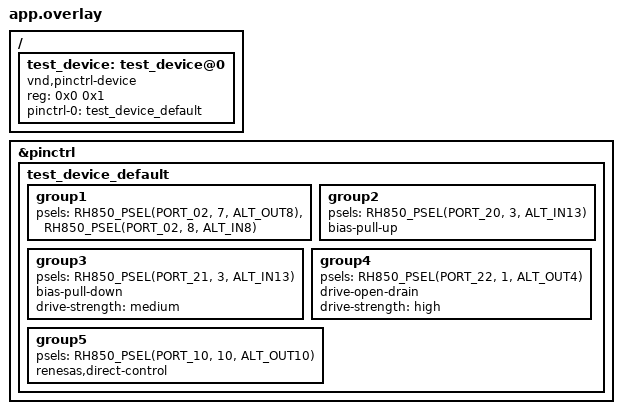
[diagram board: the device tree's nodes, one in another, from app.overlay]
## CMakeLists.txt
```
# Copyright (c) 2026 Renesas Electronics Corporation
# SPDX-License-Identifier: Apache-2.0

cmake_minimum_required(VERSION 3.20.0)
find_package(Zephyr REQUIRED HINTS $ENV{ZEPHYR_BASE})

project(pinctrl_rh850)

target_sources(app PRIVATE
  src/main.c
  ../common/test_device.c
)
```

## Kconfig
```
# Copyright (c) 2026 Renesas Electronics Corporation
# SPDX-License-Identifier: Apache-2.0

mainmenu "pinctrl RH850 DT Test"

source "Kconfig.zephyr"

config PINCTRL_TEST_NON_STATIC
	bool "Access to pin control configuration"
	select PINCTRL_NON_STATIC
	help
	  This option should be selected by unit tests that need to access the pin
	  control configuration defined in a device driver.
```

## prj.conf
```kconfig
# Copyright (c) 2026 Renesas Electronics Corporation
# SPDX-License-Identifier: Apache-2.0

CONFIG_ZTEST=y
CONFIG_PINCTRL=y
CONFIG_PINCTRL_TEST_NON_STATIC=y
```

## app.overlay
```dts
/*
 * Copyright (c) 2026 Renesas Electronics Corporation
 * SPDX-License-Identifier: Apache-2.0
 */

/ {
	#address-cells = <1>;
	#size-cells = <1>;

	test_device: test_device@0 {
		compatible = "vnd,pinctrl-device";
		reg = <0x0 0x1>;
		pinctrl-0 = <&test_device_default>;
		pinctrl-names = "default";
	};
};

&pinctrl {
	test_device_default: test_device_default {
		group1 {
			psels = <RH850_PSEL(PORT_02, 7, ALT_OUT8)>,
				<RH850_PSEL(PORT_02, 8, ALT_IN8)>;
		};

		group2 {
			psels = <RH850_PSEL(PORT_20, 3, ALT_IN13)>;
			bias-pull-up;
		};

		group3 {
			psels = <RH850_PSEL(PORT_21, 3, ALT_IN13)>;
			bias-pull-down;
			drive-strength = "medium";
		};

		group4 {
			psels = <RH850_PSEL(PORT_22, 1, ALT_OUT4)>;
			drive-open-drain;
			drive-strength = "high";
		};

		group5 {
			psels = <RH850_PSEL(PORT_10, 10, ALT_OUT10)>;
			renesas,direct-control;
		};
	};
};
```

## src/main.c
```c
/*
 * Copyright (c) 2026 Renesas Electronics Corporation
 *
 * SPDX-License-Identifier: Apache-2.0
 */

#include <zephyr/drivers/pinctrl.h>
#include <zephyr/ztest.h>
#include <bsp_api.h>

/* pin configuration for test device */
#define TEST_DEVICE DT_NODELABEL(test_device)
PINCTRL_DT_DEV_CONFIG_DECLARE(TEST_DEVICE);
static const struct pinctrl_dev_config *pcfg = PINCTRL_DT_DEV_CONFIG_GET(TEST_DEVICE);

ZTEST(pinctrl_rh850, test_dt_extract)
{
	const struct pinctrl_state *scfg;

	zassert_equal(pcfg->state_cnt, 1U);

	scfg = &pcfg->states[0];

	zassert_equal(scfg->id, PINCTRL_STATE_DEFAULT);
	zassert_equal(scfg->pin_cnt, 6U);

	zassert_equal(RH850_GET_MODE(scfg->pins[0].cfg), RH850_ALT_OUT8);
	zassert_equal(RH850_GET_PULL_UP(scfg->pins[0].cfg), 0U);
	zassert_equal(RH850_GET_PULL_DOWN(scfg->pins[0].cfg), 0U);
	zassert_equal(RH850_GET_OPEN_DRAIN(scfg->pins[0].cfg), 0U);
	zassert_equal(RH850_GET_DRIVE_STRENGTH(scfg->pins[0].cfg), RH850_DRIVE_STRENGTH_LOW);
	zassert_equal(RH850_GET_DIRECT_CONTROL(scfg->pins[0].cfg), 0U);
	zassert_equal(scfg->pins[0].port_id, BSP_IO_PORT_P02);
	zassert_equal(scfg->pins[0].pin_num, 7U);

	zassert_equal(RH850_GET_MODE(scfg->pins[1].cfg), RH850_ALT_IN8);
	zassert_equal(RH850_GET_PULL_UP(scfg->pins[1].cfg), 0U);
	zassert_equal(RH850_GET_PULL_DOWN(scfg->pins[1].cfg), 0U);
	zassert_equal(RH850_GET_OPEN_DRAIN(scfg->pins[1].cfg), 0U);
	zassert_equal(RH850_GET_DRIVE_STRENGTH(scfg->pins[1].cfg), RH850_DRIVE_STRENGTH_LOW);
	zassert_equal(RH850_GET_DIRECT_CONTROL(scfg->pins[1].cfg), 0U);
	zassert_equal(scfg->pins[1].port_id, BSP_IO_PORT_P02);
	zassert_equal(scfg->pins[1].pin_num, 8);

	zassert_equal(RH850_GET_MODE(scfg->pins[2].cfg), RH850_ALT_IN13);
	zassert_equal(RH850_GET_PULL_UP(scfg->pins[2].cfg), 1U);
	zassert_equal(RH850_GET_PULL_DOWN(scfg->pins[2].cfg), 0U);
	zassert_equal(RH850_GET_OPEN_DRAIN(scfg->pins[2].cfg), 0U);
	zassert_equal(RH850_GET_DRIVE_STRENGTH(scfg->pins[2].cfg), RH850_DRIVE_STRENGTH_LOW);
	zassert_equal(RH850_GET_DIRECT_CONTROL(scfg->pins[2].cfg), 0U);
	zassert_equal(scfg->pins[2].port_id, BSP_IO_PORT_P20);
	zassert_equal(scfg->pins[2].pin_num, 3);

	zassert_equal(RH850_GET_MODE(scfg->pins[3].cfg), RH850_ALT_IN13);
	zassert_equal(RH850_GET_PULL_UP(scfg->pins[3].cfg), 0U);
	zassert_equal(RH850_GET_PULL_DOWN(scfg->pins[3].cfg), 1U);
	zassert_equal(RH850_GET_OPEN_DRAIN(scfg->pins[3].cfg), 0U);
	zassert_equal(RH850_GET_DRIVE_STRENGTH(scfg->pins[3].cfg), RH850_DRIVE_STRENGTH_MEDIUM);
	zassert_equal(RH850_GET_DIRECT_CONTROL(scfg->pins[3].cfg), 0U);
	zassert_equal(scfg->pins[3].port_id, BSP_IO_PORT_P21);
	zassert_equal(scfg->pins[3].pin_num, 3);

	zassert_equal(RH850_GET_MODE(scfg->pins[4].cfg), RH850_ALT_OUT4);
	zassert_equal(RH850_GET_PULL_UP(scfg->pins[4].cfg), 0U);
	zassert_equal(RH850_GET_PULL_DOWN(scfg->pins[4].cfg), 0U);
	zassert_equal(RH850_GET_OPEN_DRAIN(scfg->pins[4].cfg), 2U);
	zassert_equal(RH850_GET_DRIVE_STRENGTH(scfg->pins[4].cfg), RH850_DRIVE_STRENGTH_HIGH);
	zassert_equal(RH850_GET_DIRECT_CONTROL(scfg->pins[4].cfg), 0U);
	zassert_equal(scfg->pins[4].port_id, BSP_IO_PORT_P22);
	zassert_equal(scfg->pins[4].pin_num, 1);

	zassert_equal(RH850_GET_MODE(scfg->pins[5].cfg), RH850_ALT_OUT10);
	zassert_equal(RH850_GET_PULL_UP(scfg->pins[5].cfg), 0U);
	zassert_equal(RH850_GET_PULL_DOWN(scfg->pins[5].cfg), 0U);
	zassert_equal(RH850_GET_OPEN_DRAIN(scfg->pins[5].cfg), 0U);
	zassert_equal(RH850_GET_DRIVE_STRENGTH(scfg->pins[5].cfg), RH850_DRIVE_STRENGTH_LOW);
	zassert_equal(RH850_GET_DIRECT_CONTROL(scfg->pins[5].cfg), 1U);
	zassert_equal(scfg->pins[5].port_id, BSP_IO_PORT_P10);
	zassert_equal(scfg->pins[5].pin_num, 10);
}

ZTEST_SUITE(pinctrl_rh850, NULL, NULL, NULL, NULL, NULL);
```
